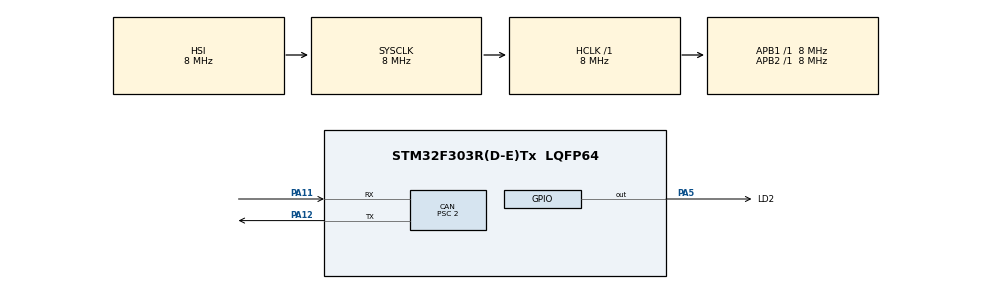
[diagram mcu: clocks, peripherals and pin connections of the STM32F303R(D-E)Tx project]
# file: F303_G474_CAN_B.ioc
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CAN.ABOM=ENABLE
CAN.AWUM=DISABLE
CAN.BS1=CAN_BS1_13TQ
CAN.BS2=CAN_BS2_2TQ
CAN.CalculateBaudRate=250000
CAN.CalculateTimeBit=4000
CAN.CalculateTimeQuantum=250.0
CAN.Mode=CAN_MODE_NORMAL
CAN.NART=DISABLE
CAN.Prescaler=2
CAN.RFLM=DISABLE
CAN.SJW=CAN_SJW_1TQ
CAN.TTCM=DISABLE
CAN.TXFP=DISABLE
Mcu.Family=STM32F3
Mcu.Name=STM32F303R(D-E)Tx
Mcu.Package=LQFP64
NVIC.PriorityGroup=NVIC_PRIORITYGROUP_4
PA11.Mode=CAN_Activate
PA11.Signal=CAN_RX
PA12.Mode=CAN_Activate
PA12.Signal=CAN_TX
PA13.Signal=SYS_JTMS-SWDIO
PA14.Signal=SYS_JTCK-SWCLK
PA5.GPIO_Label=LD2
PA5.GPIO_Mode=GPIO_MODE_OUTPUT_PP
PA5.GPIO_PuPd=GPIO_NOPULL
PA5.GPIO_Speed=GPIO_SPEED_FREQ_LOW
PA5.Signal=GPIO_Output
ProjectManager.HeapSize=0x200
ProjectManager.StackSize=0x400
ProjectManager.TargetToolchain=STM32CubeIDE
RCC.AHBFreq_Value=8000000
RCC.APB1Freq_Value=8000000
RCC.APB2Freq_Value=8000000
RCC.CortexFreq_Value=8000000
RCC.HSE_VALUE=8000000
RCC.HSI_VALUE=8000000
RCC.LSE_VALUE=32768
RCC.SYSCLKFreq_VALUE=8000000
RCC.USBFreq_Value=16000000
SYS.Debug=Serial Wire
board=custom

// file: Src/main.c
/* USER CODE BEGIN Header */
/**
  ******************************************************************************
  * @file           : main.c
  * @brief          : Main program body
  ******************************************************************************
  * @attention
  *
  * Copyright (c) 2026 STMicroelectronics.
  * All rights reserved.
  *
  * This software is licensed under terms that can be found in the LICENSE file
  * in the root directory of this software component.
  * If no LICENSE file comes with this software, it is provided AS-IS.
  *
  ******************************************************************************
  */
/* USER CODE END Header */
#include "main.h"

CAN_HandleTypeDef hcan;

void SystemClock_Config(void);
static void MX_GPIO_Init(void);
static void MX_CAN_Init(void);

int main(void)
{

  /* MCU Configuration--------------------------------------------------------*/

  /* Reset of all peripherals, Initializes the Flash interface and the Systick. */
  HAL_Init();

  /* Configure the system clock */
  SystemClock_Config();

  /* Initialize all configured peripherals */
  MX_GPIO_Init();
  MX_CAN_Init();
  /* USER CODE BEGIN 2 */
  CAN_FilterTypeDef filter = {0};
  filter.FilterBank = 0;
  filter.FilterMode = CAN_FILTERMODE_IDMASK;
  filter.FilterScale = CAN_FILTERSCALE_32BIT;
  filter.FilterFIFOAssignment = CAN_RX_FIFO0;
  filter.FilterActivation = ENABLE;  // Zero mask: accept all IDs

  if (HAL_CAN_ConfigFilter(&hcan, &filter) != HAL_OK) Error_Handler();
  if (HAL_CAN_Start(&hcan) != HAL_OK) Error_Handler();

  CAN_TxHeaderTypeDef reply = {0};
  reply.StdId = 0x124;
  reply.IDE = CAN_ID_STD;
  reply.RTR = CAN_RTR_DATA;
  reply.DLC = 1;
  uint8_t replyData[1] = {0x55};
  uint32_t mailbox;
  /* USER CODE END 2 */

  /* Infinite loop */
  while (1)
  {

    /* USER CODE BEGIN 3 */
	  if (HAL_CAN_GetRxFifoFillLevel(&hcan, CAN_RX_FIFO0) > 0) {
	      CAN_RxHeaderTypeDef rx;
	      uint8_t data[8];

	      if (HAL_CAN_GetRxMessage(&hcan, CAN_RX_FIFO0, &rx, data) == HAL_OK &&
	          rx.IDE == CAN_ID_STD && rx.StdId == 0x123) {
	          HAL_GPIO_TogglePin(GPIOA, GPIO_PIN_5);
	          if (HAL_CAN_GetTxMailboxesFreeLevel(&hcan) > 0) {
	              HAL_CAN_AddTxMessage(&hcan, &reply, replyData, &mailbox);
	          }
	      }
	  }
	  HAL_Delay(1);
  }
  /* USER CODE END 3 */
}

void SystemClock_Config(void)
{
  RCC_OscInitTypeDef RCC_OscInitStruct = {0};
  RCC_ClkInitTypeDef RCC_ClkInitStruct = {0};

  /** Initializes the RCC Oscillators according to the specified parameters
  * in the RCC_OscInitTypeDef structure.
  */
  RCC_OscInitStruct.OscillatorType = RCC_OSCILLATORTYPE_HSI;
  RCC_OscInitStruct.HSIState = RCC_HSI_ON;
  RCC_OscInitStruct.HSICalibrationValue = RCC_HSICALIBRATION_DEFAULT;
  RCC_OscInitStruct.PLL.PLLState = RCC_PLL_NONE;
  if (HAL_RCC_OscConfig(&RCC_OscInitStruct) != HAL_OK)
  {
    Error_Handler();
  }

  /** Initializes the CPU, AHB and APB buses clocks
  */
  RCC_ClkInitStruct.ClockType = RCC_CLOCKTYPE_HCLK|RCC_CLOCKTYPE_SYSCLK
                              |RCC_CLOCKTYPE_PCLK1|RCC_CLOCKTYPE_PCLK2;
  RCC_ClkInitStruct.SYSCLKSource = RCC_SYSCLKSOURCE_HSI;
  RCC_ClkInitStruct.AHBCLKDivider = RCC_SYSCLK_DIV1;
  RCC_ClkInitStruct.APB1CLKDivider = RCC_HCLK_DIV1;
  RCC_ClkInitStruct.APB2CLKDivider = RCC_HCLK_DIV1;

  if (HAL_RCC_ClockConfig(&RCC_ClkInitStruct, FLASH_LATENCY_0) != HAL_OK)
  {
    Error_Handler();
  }
}

static void MX_CAN_Init(void)
{

  hcan.Instance = CAN;
  hcan.Init.Prescaler = 2;
  hcan.Init.Mode = CAN_MODE_NORMAL;
  hcan.Init.SyncJumpWidth = CAN_SJW_1TQ;
  hcan.Init.TimeSeg1 = CAN_BS1_13TQ;
  hcan.Init.TimeSeg2 = CAN_BS2_2TQ;
  hcan.Init.TimeTriggeredMode = DISABLE;
  hcan.Init.AutoBusOff = ENABLE;
  hcan.Init.AutoWakeUp = DISABLE;
  hcan.Init.AutoRetransmission = DISABLE;
  hcan.Init.ReceiveFifoLocked = DISABLE;
  hcan.Init.TransmitFifoPriority = DISABLE;
  if (HAL_CAN_Init(&hcan) != HAL_OK)
  {
    Error_Handler();
  }

}

static void MX_GPIO_Init(void)
{
  GPIO_InitTypeDef GPIO_InitStruct = {0};

  /* GPIO Ports Clock Enable */
  __HAL_RCC_GPIOA_CLK_ENABLE();

  /*Configure GPIO pin Output Level */
  HAL_GPIO_WritePin(LD2_GPIO_Port, LD2_Pin, GPIO_PIN_RESET);

  /*Configure GPIO pin : LD2_Pin */
  GPIO_InitStruct.Pin = LD2_Pin;
  GPIO_InitStruct.Mode = GPIO_MODE_OUTPUT_PP;
  GPIO_InitStruct.Pull = GPIO_NOPULL;
  GPIO_InitStruct.Speed = GPIO_SPEED_FREQ_LOW;
  HAL_GPIO_Init(LD2_GPIO_Port, &GPIO_InitStruct);

}

void Error_Handler(void)
{
  __disable_irq();
  while (1)
  {
  }
}
